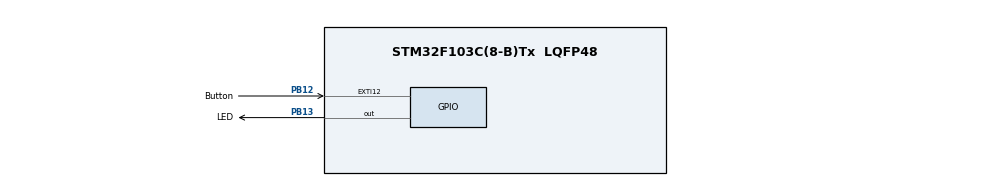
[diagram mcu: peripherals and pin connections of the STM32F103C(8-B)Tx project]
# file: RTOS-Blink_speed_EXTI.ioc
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FREERTOS.Queues01=Queue01,8,uint8_t,0,Dynamic,NULL,NULL
FREERTOS.Tasks01=ledBlink,24,256,StartLedBlink,Default,NULL,Dynamic,NULL,NULL;readButton,8,256,StartReadButton,Default,NULL,Dynamic,NULL,NULL
Mcu.Family=STM32F1
Mcu.Name=STM32F103C(8-B)Tx
Mcu.Package=LQFP48
NVIC.EXTI15_10_IRQn=true\:5\:0\:false\:false\:true\:true\:true\:true\:true
NVIC.PriorityGroup=NVIC_PRIORITYGROUP_4
NVIC.TIM4_IRQn=true\:15\:0\:false\:false\:true\:false\:false\:true\:true
NVIC.TimeBase=TIM4_IRQn
NVIC.TimeBaseIP=TIM4
PB12.GPIO_Label=Button
PB12.Signal=GPXTI12
PB13.GPIO_Label=LED
PB13.Signal=GPIO_Output
ProjectManager.HeapSize=0x200
ProjectManager.StackSize=0x400
ProjectManager.TargetToolchain=STM32CubeIDE
RCC.APB1Freq_Value=8000000
RCC.APB2Freq_Value=8000000
VP_FREERTOS_VS_CMSIS_V2.Mode=CMSIS_V2
VP_SYS_VS_ND.Mode=No_Debug
VP_SYS_VS_tim4.Mode=TIM4
board=custom

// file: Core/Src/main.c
/* USER CODE BEGIN Header */
/**
  ******************************************************************************
  * @file           : main.c
  * @brief          : Main program body
  ******************************************************************************
  * @attention
  *
  * Copyright (c) 2025 STMicroelectronics.
  * All rights reserved.
  *
  * This software is licensed under terms that can be found in the LICENSE file
  * in the root directory of this software component.
  * If no LICENSE file comes with this software, it is provided AS-IS.
  *
  ******************************************************************************
  */
/* USER CODE END Header */
#include "main.h"
#include "cmsis_os.h"

/* Definitions for ledBlink */
osThreadId_t ledBlinkHandle;
const osThreadAttr_t ledBlink_attributes = {
  .name = "ledBlink",
  .stack_size = 256 * 4,
  .priority = (osPriority_t) osPriorityNormal,
};
/* Definitions for readButton */
osThreadId_t readButtonHandle;
const osThreadAttr_t readButton_attributes = {
  .name = "readButton",
  .stack_size = 256 * 4,
  .priority = (osPriority_t) osPriorityLow,
};
/* Definitions for Queue01 */
osMessageQueueId_t Queue01Handle;
const osMessageQueueAttr_t Queue01_attributes = {
  .name = "Queue01"
};

void SystemClock_Config(void);
static void MX_GPIO_Init(void);
void StartLedBlink(void *argument);
void StartReadButton(void *argument);

int main(void)
{

  /* MCU Configuration--------------------------------------------------------*/

  /* Reset of all peripherals, Initializes the Flash interface and the Systick. */
  HAL_Init();

  /* Configure the system clock */
  SystemClock_Config();

  /* Initialize all configured peripherals */
  MX_GPIO_Init();

  /* Init scheduler */
  osKernelInitialize();

  /* Create the queue(s) */
  /* creation of Queue01 */
  Queue01Handle = osMessageQueueNew (8, sizeof(uint16_t), &Queue01_attributes);

  /* Create the thread(s) */
  /* creation of ledBlink */
  ledBlinkHandle = osThreadNew(StartLedBlink, NULL, &ledBlink_attributes);

  /* creation of readButton */
  readButtonHandle = osThreadNew(StartReadButton, NULL, &readButton_attributes);

  /* Start scheduler */
  osKernelStart();

  /* We should never get here as control is now taken by the scheduler */

  /* Infinite loop */
  while (1)
  {

  }
}

void SystemClock_Config(void)
{
  RCC_OscInitTypeDef RCC_OscInitStruct = {0};
  RCC_ClkInitTypeDef RCC_ClkInitStruct = {0};

  /** Initializes the RCC Oscillators according to the specified parameters
  * in the RCC_OscInitTypeDef structure.
  */
  RCC_OscInitStruct.OscillatorType = RCC_OSCILLATORTYPE_HSI;
  RCC_OscInitStruct.HSIState = RCC_HSI_ON;
  RCC_OscInitStruct.HSICalibrationValue = RCC_HSICALIBRATION_DEFAULT;
  RCC_OscInitStruct.PLL.PLLState = RCC_PLL_NONE;
  if (HAL_RCC_OscConfig(&RCC_OscInitStruct) != HAL_OK)
  {
    Error_Handler();
  }

  /** Initializes the CPU, AHB and APB buses clocks
  */
  RCC_ClkInitStruct.ClockType = RCC_CLOCKTYPE_HCLK|RCC_CLOCKTYPE_SYSCLK
                              |RCC_CLOCKTYPE_PCLK1|RCC_CLOCKTYPE_PCLK2;
  RCC_ClkInitStruct.SYSCLKSource = RCC_SYSCLKSOURCE_HSI;
  RCC_ClkInitStruct.AHBCLKDivider = RCC_SYSCLK_DIV1;
  RCC_ClkInitStruct.APB1CLKDivider = RCC_HCLK_DIV1;
  RCC_ClkInitStruct.APB2CLKDivider = RCC_HCLK_DIV1;

  if (HAL_RCC_ClockConfig(&RCC_ClkInitStruct, FLASH_LATENCY_0) != HAL_OK)
  {
    Error_Handler();
  }
}

static void MX_GPIO_Init(void)
{
  GPIO_InitTypeDef GPIO_InitStruct = {0};

  /* GPIO Ports Clock Enable */
  __HAL_RCC_GPIOB_CLK_ENABLE();

  /*Configure GPIO pin Output Level */
  HAL_GPIO_WritePin(LED_GPIO_Port, LED_Pin, GPIO_PIN_RESET);

  /*Configure GPIO pin : Button_Pin */
  GPIO_InitStruct.Pin = Button_Pin;
  GPIO_InitStruct.Mode = GPIO_MODE_IT_RISING;
  GPIO_InitStruct.Pull = GPIO_NOPULL;
  HAL_GPIO_Init(Button_GPIO_Port, &GPIO_InitStruct);

  /*Configure GPIO pin : LED_Pin */
  GPIO_InitStruct.Pin = LED_Pin;
  GPIO_InitStruct.Mode = GPIO_MODE_OUTPUT_PP;
  GPIO_InitStruct.Pull = GPIO_NOPULL;
  GPIO_InitStruct.Speed = GPIO_SPEED_FREQ_LOW;
  HAL_GPIO_Init(LED_GPIO_Port, &GPIO_InitStruct);

  /* EXTI interrupt init*/
  HAL_NVIC_SetPriority(EXTI15_10_IRQn, 5, 0);
  HAL_NVIC_EnableIRQ(EXTI15_10_IRQn);

}

/* USER CODE BEGIN 4 */
volatile uint8_t button_flag = 0;
volatile uint32_t now = 0;
volatile uint32_t previous = 0;
void HAL_GPIO_EXTI_Callback(uint16_t GPIO_Pin)
{
  if(GPIO_Pin == Button_Pin){
	  now = osKernelGetTickCount();
	  if(now - previous > 100){
		  button_flag = 1;
		  previous = now;
	  }
  }
}
/* USER CODE END 4 */

void StartLedBlink(void *argument)
{
  /* USER CODE BEGIN 5 */
	uint16_t delay = 500;
  /* Infinite loop */
  for(;;)
  {
	  osMessageQueueGet(Queue01Handle, &delay, NULL, delay);
	   HAL_GPIO_TogglePin(GPIOB, LED_Pin);
	   osDelay(delay);
	   HAL_GPIO_TogglePin(GPIOB, LED_Pin);
	   osDelay(delay);

  }
  /* USER CODE END 5 */
}

void StartReadButton(void *argument)
{
  /* USER CODE BEGIN StartReadButton */
	uint8_t index = 0;
	uint16_t delays[] = {200,750,1500};
  /* Infinite loop */
  for(;;)
  {
	  if(button_flag){
		  button_flag = 0;

		  index++;

		  if(index >= 3){
			  index = 0;
		  }
		  uint16_t delay = delays[index];
		  osMessageQueuePut(Queue01Handle, &delay, 0, 0);
	  }
    osDelay(10);
  }
  /* USER CODE END StartReadButton */
}

void HAL_TIM_PeriodElapsedCallback(TIM_HandleTypeDef *htim)
{
  if (htim->Instance == TIM4)
  {
    HAL_IncTick();
  }
}

void Error_Handler(void)
{
  __disable_irq();
  while (1)
  {
  }
}
